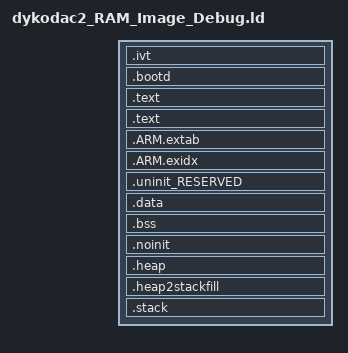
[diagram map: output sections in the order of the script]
/*
 * GENERATED FILE - DO NOT EDIT
 * Copyright (c) 2008-2013 Code Red Technologies Ltd,
 * Copyright 2015, 2018-2019 NXP
 * (c) NXP Semiconductors 2013-2020
 * Generated linker script file for MIMXRT1011xxxxx
 * Created from linkscript.ldt by FMCreateLinkLibraries
 * Using Freemarker v2.3.23
 * MCUXpresso IDE v11.2.1 [Build 4149] [2020-10-07] on 12-Dec-2020 17:36:58
 */

INCLUDE "./linkscripts/dykodac2_Debug_library.ld"
INCLUDE "./linkscripts/dykodac2_RAM_Debug_memory.ld"

ENTRY(ResetISR)

SECTIONS
{
		.ivt : ALIGN(4)
	{
		LONG(__section_table_end);
		LONG(0);
		LONG(0);
		LONG(LOADADDR(.bootd));
		LONG(LOADADDR(.ivt));
		LONG(0);
		LONG(0);
	} > SRAM_OC
	
	.bootd : ALIGN(4)
	{
		LONG(_image_start);
		LONG(_image_size);
		LONG(0);
	} > SRAM_OC
	
     /* MAIN TEXT SECTION */
    .text : ALIGN(4)
    {
        FILL(0xff)
        __vectors_start__ = ABSOLUTE(.) ;
        KEEP(*(.isr_vector))
        /* Global Section Table */
        . = ALIGN(4) ;
        __section_table_start = .;
        __data_section_table = .;
        LONG(LOADADDR(.data));
        LONG(    ADDR(.data));
        LONG(  SIZEOF(.data));
        __data_section_table_end = .;
        __bss_section_table = .;
        LONG(    ADDR(.bss));
        LONG(  SIZEOF(.bss));
        __bss_section_table_end = .;
        __section_table_end = . ;
        /* End of Global Section Table */

        *(.after_vectors*)

    } > SRAM_OC

    .text : ALIGN(4)
    {
       *(.text*)
       *(.rodata .rodata.* .constdata .constdata.*)
       . = ALIGN(4);
            /* C++ constructors etc */
            . = ALIGN(4);
            KEEP(*(.init))
            
            . = ALIGN(4);
            __preinit_array_start = .;
            KEEP (*(.preinit_array))
            __preinit_array_end = .;
            
            . = ALIGN(4);
            __init_array_start = .;
            KEEP (*(SORT(.init_array.*)))
            KEEP (*(.init_array))
            __init_array_end = .;
            
            KEEP(*(.fini));
            
            . = ALIGN(4);
            KEEP (*crtbegin.o(.ctors))
            KEEP (*(EXCLUDE_FILE (*crtend.o) .ctors))
            KEEP (*(SORT(.ctors.*)))
            KEEP (*crtend.o(.ctors))
            
            . = ALIGN(4);
            KEEP (*crtbegin.o(.dtors))
            KEEP (*(EXCLUDE_FILE (*crtend.o) .dtors))
            KEEP (*(SORT(.dtors.*)))
            KEEP (*crtend.o(.dtors))
            . = ALIGN(4);
            /* End C++ */
    } > SRAM_OC
    /*
     * for exception handling/unwind - some Newlib functions (in common
     * with C++ and STDC++) use this.
     */
    .ARM.extab : ALIGN(4)
    {
        *(.ARM.extab* .gnu.linkonce.armextab.*)
    } > SRAM_OC

    .ARM.exidx : ALIGN(4)
    {
        __exidx_start = .;
        *(.ARM.exidx* .gnu.linkonce.armexidx.*)
        __exidx_end = .;
    } > SRAM_OC
 
    _etext = .;
        
    /* MAIN DATA SECTION */
    .uninit_RESERVED (NOLOAD) : ALIGN(4)
    {
        _start_uninit_RESERVED = .;
        KEEP(*(.bss.$RESERVED*))
       . = ALIGN(4) ;
        _end_uninit_RESERVED = .;
    } > SRAM_OC AT> SRAM_OC

    /* Main DATA section (SRAM_OC) */
    .data : ALIGN(4)
    {
       FILL(0xff)
       _data = . ;
       PROVIDE(__start_data_RAM = .) ;
       PROVIDE(__start_data_SRAM_OC = .) ;
       *(vtable)
       *(.ramfunc*)
       KEEP(*(CodeQuickAccess))
       KEEP(*(DataQuickAccess))
       *(RamFunction)
       *(.data*)
       . = ALIGN(4) ;
       _edata = . ;
       PROVIDE(__end_data_RAM = .) ;
       PROVIDE(__end_data_SRAM_OC = .) ;
    } > SRAM_OC AT>SRAM_OC

    /* MAIN BSS SECTION */
    .bss : ALIGN(4)
    {
        _bss = .;
        PROVIDE(__start_bss_RAM = .) ;
        PROVIDE(__start_bss_SRAM_OC = .) ;
        *(.bss*)
        *(COMMON)
        . = ALIGN(4) ;
        _ebss = .;
        PROVIDE(__end_bss_RAM = .) ;
        PROVIDE(__end_bss_SRAM_OC = .) ;
        PROVIDE(end = .);
    } > SRAM_OC AT> SRAM_OC

    /* DEFAULT NOINIT SECTION */
    .noinit (NOLOAD): ALIGN(4)
    {
        _noinit = .;
        PROVIDE(__start_noinit_RAM = .) ;
        PROVIDE(__start_noinit_SRAM_OC = .) ;
        *(.noinit*)
         . = ALIGN(4) ;
        _end_noinit = .;
       PROVIDE(__end_noinit_RAM = .) ;
       PROVIDE(__end_noinit_SRAM_OC = .) ;        
    } > SRAM_OC AT> SRAM_OC

    /* Reserve and place Heap within memory map */
    _HeapSize = 0x800;
    .heap :  ALIGN(4)
    {
        _pvHeapStart = .;
        . += _HeapSize;
        . = ALIGN(4);
        _pvHeapLimit = .;
    } > SRAM_OC

     _StackSize = 0x800;
     /* Reserve space in memory for Stack */
    .heap2stackfill  :
    {
        . += _StackSize;
    } > SRAM_OC
    /* Locate actual Stack in memory map */
    .stack ORIGIN(SRAM_OC) + LENGTH(SRAM_OC) - _StackSize - 0:  ALIGN(4)
    {
        _vStackBase = .;
        . = ALIGN(4);
        _vStackTop = . + _StackSize;
    } > SRAM_OC

    /* Provide basic symbols giving location and size of main text
     * block, including initial values of RW data sections. Note that
     * these will need extending to give a complete picture with
     * complex images (e.g multiple Flash banks).
     */
    _image_start = LOADADDR(.text);
    _image_end = LOADADDR(.data) + SIZEOF(.data);
    _image_size = _image_end - _image_start;
}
